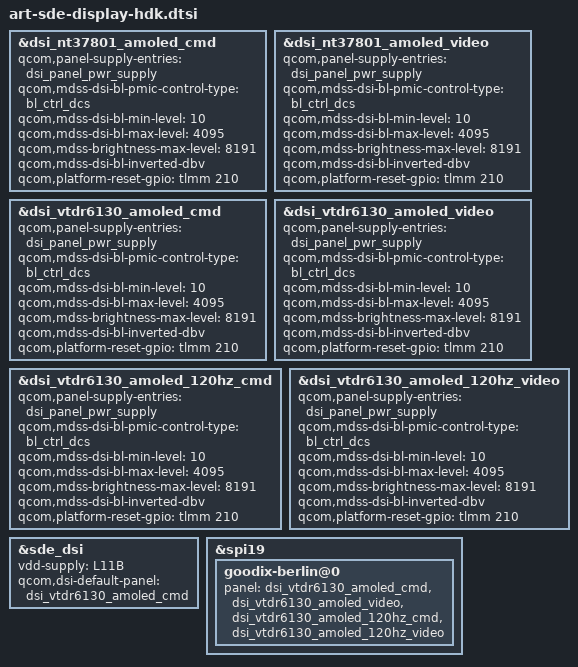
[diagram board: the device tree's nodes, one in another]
// SPDX-License-Identifier: BSD-3-Clause
/*
 * Copyright (c) Qualcomm Technologies, Inc. and/or its subsidiaries.
 */

#include "art-sde-display.dtsi"

&dsi_nt37801_amoled_cmd {
	qcom,panel-supply-entries = <&dsi_panel_pwr_supply>;
	qcom,mdss-dsi-bl-pmic-control-type = "bl_ctrl_dcs";
	qcom,mdss-dsi-bl-min-level = <10>;
	qcom,mdss-dsi-bl-max-level = <4095>;
	qcom,mdss-brightness-max-level = <8191>;
	qcom,mdss-dsi-bl-inverted-dbv;
	qcom,platform-reset-gpio = <&tlmm 210 0>;
};

&dsi_nt37801_amoled_video {
	qcom,panel-supply-entries = <&dsi_panel_pwr_supply>;
	qcom,mdss-dsi-bl-pmic-control-type = "bl_ctrl_dcs";
	qcom,mdss-dsi-bl-min-level = <10>;
	qcom,mdss-dsi-bl-max-level = <4095>;
	qcom,mdss-brightness-max-level = <8191>;
	qcom,mdss-dsi-bl-inverted-dbv;
	qcom,platform-reset-gpio = <&tlmm 210 0>;
};

&dsi_vtdr6130_amoled_cmd {
	qcom,panel-supply-entries = <&dsi_panel_pwr_supply>;
	qcom,mdss-dsi-bl-pmic-control-type = "bl_ctrl_dcs";
	qcom,mdss-dsi-bl-min-level = <10>;
	qcom,mdss-dsi-bl-max-level = <4095>;
	qcom,mdss-brightness-max-level = <8191>;
	qcom,mdss-dsi-bl-inverted-dbv;
	qcom,platform-reset-gpio = <&tlmm 210 0>;
};

&dsi_vtdr6130_amoled_video {
	qcom,panel-supply-entries = <&dsi_panel_pwr_supply>;
	qcom,mdss-dsi-bl-pmic-control-type = "bl_ctrl_dcs";
	qcom,mdss-dsi-bl-min-level = <10>;
	qcom,mdss-dsi-bl-max-level = <4095>;
	qcom,mdss-brightness-max-level = <8191>;
	qcom,mdss-dsi-bl-inverted-dbv;
	qcom,platform-reset-gpio = <&tlmm 210 0>;
};

&dsi_vtdr6130_amoled_120hz_cmd {
	qcom,panel-supply-entries = <&dsi_panel_pwr_supply>;
	qcom,mdss-dsi-bl-pmic-control-type = "bl_ctrl_dcs";
	qcom,mdss-dsi-bl-min-level = <10>;
	qcom,mdss-dsi-bl-max-level = <4095>;
	qcom,mdss-brightness-max-level = <8191>;
	qcom,mdss-dsi-bl-inverted-dbv;
	qcom,platform-reset-gpio = <&tlmm 210 0>;
};

&dsi_vtdr6130_amoled_120hz_video {
	qcom,panel-supply-entries = <&dsi_panel_pwr_supply>;
	qcom,mdss-dsi-bl-pmic-control-type = "bl_ctrl_dcs";
	qcom,mdss-dsi-bl-min-level = <10>;
	qcom,mdss-dsi-bl-max-level = <4095>;
	qcom,mdss-brightness-max-level = <8191>;
	qcom,mdss-dsi-bl-inverted-dbv;
	qcom,platform-reset-gpio = <&tlmm 210 0>;
};

&sde_dsi {
	vdd-supply = <&L11B>;
	qcom,dsi-default-panel = <&dsi_vtdr6130_amoled_cmd>;
};

&spi19 {
	goodix-berlin@0 {
		panel = <&dsi_vtdr6130_amoled_cmd
			&dsi_vtdr6130_amoled_video
			&dsi_vtdr6130_amoled_120hz_cmd
			&dsi_vtdr6130_amoled_120hz_video>;
	};
};
